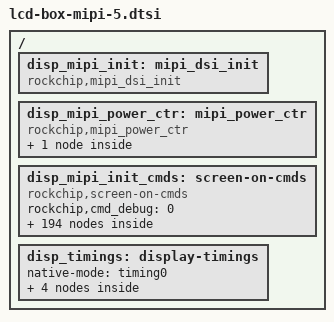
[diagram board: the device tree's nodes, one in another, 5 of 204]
/*
 * RockChip. LCD_BOX mipi 5.1 720*1280 4line
 *
 */
#include <dt-bindings/input/input.h>
/ {

        /* about mipi */
		disp_mipi_init: mipi_dsi_init{
					compatible = "rockchip,mipi_dsi_init";
					rockchip,screen_init	= <0>;
					rockchip,dsi_lane		= <4>;
					rockchip,dsi_hs_clk		= <450>;//
					rockchip,mipi_dsi_num	= <1>;
		};
		disp_mipi_power_ctr: mipi_power_ctr {
					compatible = "rockchip,mipi_power_ctr";
					mipi_lcd_rst:mipi_lcd_rst {
							compatible = "rockchip,lcd_rst";
							rockchip,gpios = <&gpio8 GPIO_A7 GPIO_ACTIVE_HIGH>;
							rockchip,delay = <100>;
					};
		};
		disp_mipi_init_cmds: screen-on-cmds {
			compatible = "rockchip,screen-on-cmds";
			rockchip,cmd_debug = <0>;

			rockchip,on-cmds1 {
			compatible = "rockchip,on-cmds";
			rockchip,cmd_type = <LPDT>;
			rockchip,dsi_id = <0>;        
			rockchip,cmd = <0x39 0xFF 0x98 0x81 0x03>;
			rockchip,cmd_delay = <0>;
		    };

		    rockchip,on-cmds2 {
			compatible = "rockchip,on-cmds";
			rockchip,cmd_type = <LPDT>;
			rockchip,dsi_id = <0>;        
			rockchip,cmd = <0x15 0x01 0x00>;
			rockchip,cmd_delay = <0>;
		    };

		    rockchip,on-cmds3 {
			compatible = "rockchip,on-cmds";
			rockchip,cmd_type = <LPDT>;
			rockchip,dsi_id = <0>;     
			rockchip,cmd = <0x15 0x02 0X00>;
			rockchip,cmd_delay = <0>;
		    };

		    rockchip,on-cmds4 {
			compatible = "rockchip,on-cmds";
			rockchip,cmd_type = <LPDT>;
			rockchip,dsi_id = <0>;        
			rockchip,cmd = <0x15 0x03 0X53>;
			rockchip,cmd_delay = <0>;
		    };

		    rockchip,on-cmds5 {
			compatible = "rockchip,on-cmds";
			rockchip,cmd_type = <LPDT>;
			rockchip,dsi_id = <0>;        
			rockchip,cmd = <0x15 0X04 0X00>;
			rockchip,cmd_delay = <0>;
		    };

		    rockchip,on-cmds6 {
			compatible = "rockchip,on-cmds";
			rockchip,cmd_type = <LPDT>;
			rockchip,dsi_id = <0>;        
			rockchip,cmd = <0x15 0x05 0X00>;
			rockchip,cmd_delay = <0>;
		    };

		    rockchip,on-cmds7 {
			compatible = "rockchip,on-cmds";
			rockchip,cmd_type = <LPDT>;
			rockchip,dsi_id = <0>;      
			rockchip,cmd = <0x15 0x06 0x08>;
			rockchip,cmd_delay = <0>;
		    };

		    rockchip,on-cmds8 {
			compatible = "rockchip,on-cmds";
			rockchip,cmd_type = <LPDT>;
			rockchip,dsi_id = <0>;        
			rockchip,cmd = <0x15 0x07 0x00>;
			rockchip,cmd_delay = <0>;
		    };

		    rockchip,on-cmds9 {
			compatible = "rockchip,on-cmds";
			rockchip,cmd_type = <LPDT>;
			rockchip,dsi_id = <0>;        
			rockchip,cmd = <0x15 0x08 0x00>;
			rockchip,cmd_delay = <0>;
		    };
//////////////////////////////////////////////////
		    rockchip,on-cmds10 {
			compatible = "rockchip,on-cmds";
			rockchip,cmd_type = <LPDT>;
			rockchip,dsi_id = <0>;       
			rockchip,cmd = <0x15 0x09 0x00>;
			rockchip,cmd_delay = <0>;
		    };


		    rockchip,on-cmds11 {
			compatible = "rockchip,on-cmds";
			rockchip,cmd_type = <LPDT>;
			rockchip,dsi_id = <0>; 
			rockchip,cmd = <0x15 0X0A 0X00>;
			rockchip,cmd_delay = <0>;
		    };

		    rockchip,on-cmds12 {
			compatible = "rockchip,on-cmds";
			rockchip,cmd_type = <LPDT>;
			rockchip,dsi_id = <0>;      
			rockchip,cmd = <0x15 0X0b 0X00>;
			rockchip,cmd_delay = <0>;
		    };

		    rockchip,on-cmds13 {
			compatible = "rockchip,on-cmds";
			rockchip,cmd_type = <LPDT>;
			rockchip,dsi_id = <0>;        
			rockchip,cmd = <0x15 0x0C 0x00>;
			rockchip,cmd_delay = <0>;
		    };

		    rockchip,on-cmds14 {
			compatible = "rockchip,on-cmds";
			rockchip,cmd_type = <LPDT>;
			rockchip,dsi_id = <0>;    
			rockchip,cmd = <0x15 0x0d 0x00>;
			rockchip,cmd_delay = <0>;
		    };

		    rockchip,on-cmds15 {
			compatible = "rockchip,on-cmds";
			rockchip,cmd_type = <LPDT>;
			rockchip,dsi_id = <0>;     	  
			rockchip,cmd = <0x15  0X0e 0X00>;
			rockchip,cmd_delay = <0>;
		    };

		    rockchip,on-cmds16 {
			compatible = "rockchip,on-cmds";
			rockchip,cmd_type = <LPDT>;
			rockchip,dsi_id = <0>;    
			rockchip,cmd = <0x15 0x0f 0x26>;
			rockchip,cmd_delay = <0>;
		    };

		    //~~~~

		    rockchip,on-cmds17 {
			compatible = "rockchip,on-cmds";
			rockchip,cmd_type = <LPDT>;
			rockchip,dsi_id = <0>;       
			rockchip,cmd = <0x15 0x10 0x26>;
			rockchip,cmd_delay = <0>;
		    };

		    rockchip,on-cmds18 {
			compatible = "rockchip,on-cmds";
			rockchip,cmd_type = <LPDT>;
			rockchip,dsi_id = <0>;       
			rockchip,cmd = <0x15 0x11 0x00>;
			rockchip,cmd_delay = <0>;
		    };
		    rockchip,on-cmds19 {
			compatible = "rockchip,on-cmds";
			rockchip,cmd_type = <LPDT>;
			rockchip,dsi_id = <0>;       
			rockchip,cmd = <0x15 0x12 0x00>;
			rockchip,cmd_delay = <0>;
		    };
		    rockchip,on-cmds20 {
			compatible = "rockchip,on-cmds";
			rockchip,cmd_type = <LPDT>;
			rockchip,dsi_id = <0>;       
			rockchip,cmd = <0x15 0x13 0x00>;
			rockchip,cmd_delay = <0>;
		    };
		    rockchip,on-cmds21 {
			compatible = "rockchip,on-cmds";
			rockchip,cmd_type = <LPDT>;
			rockchip,dsi_id = <0>;       
			rockchip,cmd = <0x15 0x14 0x00>;
			rockchip,cmd_delay = <0>;
		    };
		    rockchip,on-cmds22 {
			compatible = "rockchip,on-cmds";
			rockchip,cmd_type = <LPDT>;
			rockchip,dsi_id = <0>;       
			rockchip,cmd = <0x15 0x15 0x00>;
			rockchip,cmd_delay = <0>;
		    };
		    rockchip,on-cmds23 {
			compatible = "rockchip,on-cmds";
			rockchip,cmd_type = <LPDT>;
			rockchip,dsi_id = <0>;       
			rockchip,cmd = <0x15 0x16 0x00>;
			rockchip,cmd_delay = <0>;
		    };
		    rockchip,on-cmds24 {
			compatible = "rockchip,on-cmds";
			rockchip,cmd_type = <LPDT>;
			rockchip,dsi_id = <0>;       
			rockchip,cmd = <0x15 0x17 0x00>;
			rockchip,cmd_delay = <0>;
		    };

		    rockchip,on-cmds25 {
			compatible = "rockchip,on-cmds";
			rockchip,cmd_type = <LPDT>;
			rockchip,dsi_id = <0>;       
			rockchip,cmd = <0x15 0x18 0x00>;
			rockchip,cmd_delay = <0>;
		    };
		    rockchip,on-cmds26 {
			compatible = "rockchip,on-cmds";
			rockchip,cmd_type = <LPDT>;
			rockchip,dsi_id = <0>;       
			rockchip,cmd = <0x15 0x19 0x00>;
			rockchip,cmd_delay = <0>;
		    };
		    rockchip,on-cmds27 {
			compatible = "rockchip,on-cmds";
			rockchip,cmd_type = <LPDT>;
			rockchip,dsi_id = <0>;       
			rockchip,cmd = <0x15 0x1a 0x00>;
			rockchip,cmd_delay = <0>;
		    };
		    rockchip,on-cmds28 {
			compatible = "rockchip,on-cmds";
			rockchip,cmd_type = <LPDT>;
			rockchip,dsi_id = <0>;       
			rockchip,cmd = <0x15 0x1b 0x00>;
			rockchip,cmd_delay = <0>;
		    };

		    rockchip,on-cmds29 {
			compatible = "rockchip,on-cmds";
			rockchip,cmd_type = <LPDT>;
			rockchip,dsi_id = <0>;       
			rockchip,cmd = <0x15 0x1c 0x00>;
			rockchip,cmd_delay = <0>;
		    };
		    rockchip,on-cmds30 {
			compatible = "rockchip,on-cmds";
			rockchip,cmd_type = <LPDT>;
			rockchip,dsi_id = <0>;       
			rockchip,cmd = <0x15 0x1d 0x00>;
			rockchip,cmd_delay = <0>;
		    };
		    rockchip,on-cmds31 {
			compatible = "rockchip,on-cmds";
			rockchip,cmd_type = <LPDT>;
			rockchip,dsi_id = <0>;       
			rockchip,cmd = <0x15 0x1e 0x40>;
			rockchip,cmd_delay = <0>;
		    };
		    rockchip,on-cmds32 {
			compatible = "rockchip,on-cmds";
			rockchip,cmd_type = <LPDT>;
			rockchip,dsi_id = <0>;       
			rockchip,cmd = <0x15 0x1f 0xc0>;
			rockchip,cmd_delay = <0>;
		    };

		    /////////////////////////////////////
		    

		    rockchip,on-cmds33 {
			compatible = "rockchip,on-cmds";
			rockchip,cmd_type = <LPDT>;
			rockchip,dsi_id = <0>;       
			rockchip,cmd = <0x15 0x20 0x06>;
			rockchip,cmd_delay = <0>;
		    };


		    rockchip,on-cmds34 {
			compatible = "rockchip,on-cmds";
			rockchip,cmd_type = <LPDT>;
			rockchip,dsi_id = <0>; 
			rockchip,cmd = <0x15 0X21 0X01>;
			rockchip,cmd_delay = <0>;
		    };

		    rockchip,on-cmds35 {
			compatible = "rockchip,on-cmds";
			rockchip,cmd_type = <LPDT>;
			rockchip,dsi_id = <0>;      
			rockchip,cmd = <0x15 0X22 0X07>;
			rockchip,cmd_delay = <0>;
		    };

		    rockchip,on-cmds36 {
			compatible = "rockchip,on-cmds";
			rockchip,cmd_type = <LPDT>;
			rockchip,dsi_id = <0>;        
			rockchip,cmd = <0x15 0x23 0x00>;
			rockchip,cmd_delay = <0>;
		    };

		    rockchip,on-cmds37 {
			compatible = "rockchip,on-cmds";
			rockchip,cmd_type = <LPDT>;
			rockchip,dsi_id = <0>;    
			rockchip,cmd = <0x15 0x24 0x8a>;
			rockchip,cmd_delay = <0>;
		    };

		    rockchip,on-cmds38 {
			compatible = "rockchip,on-cmds";
			rockchip,cmd_type = <LPDT>;
			rockchip,dsi_id = <0>;     	  
			rockchip,cmd = <0x15  0X25 0x8a>;
			rockchip,cmd_delay = <0>;
		    };

		    rockchip,on-cmds39 {
			compatible = "rockchip,on-cmds";
			rockchip,cmd_type = <LPDT>;
			rockchip,dsi_id = <0>;    
			rockchip,cmd = <0x15 0x26 0x00>;
			rockchip,cmd_delay = <0>;
		    };

		    //~~~~

		    rockchip,on-cmds40 {
			compatible = "rockchip,on-cmds";
			rockchip,cmd_type = <LPDT>;
			rockchip,dsi_id = <0>;       
			rockchip,cmd = <0x15 0x27 0x00>;
			rockchip,cmd_delay = <0>;
		    };

		    rockchip,on-cmds41 {
			compatible = "rockchip,on-cmds";
			rockchip,cmd_type = <LPDT>;
			rockchip,dsi_id = <0>;       
			rockchip,cmd = <0x15 0x28 0x33>;
			rockchip,cmd_delay = <0>;
		    };
		    rockchip,on-cmds42 {
			compatible = "rockchip,on-cmds";
			rockchip,cmd_type = <LPDT>;
			rockchip,dsi_id = <0>;       
			rockchip,cmd = <0x15 0x29 0x33>;
			rockchip,cmd_delay = <0>;
		    };
		    rockchip,on-cmds43 {
			compatible = "rockchip,on-cmds";
			rockchip,cmd_type = <LPDT>;
			rockchip,dsi_id = <0>;       
			rockchip,cmd = <0x15 0x2a 0x00>;
			rockchip,cmd_delay = <0>;
		    };
		    rockchip,on-cmds44 {
			compatible = "rockchip,on-cmds";
			rockchip,cmd_type = <LPDT>;
			rockchip,dsi_id = <0>;       
			rockchip,cmd = <0x15 0x2b 0x00>;
			rockchip,cmd_delay = <0>;
		    };
		    rockchip,on-cmds45 {
			compatible = "rockchip,on-cmds";
			rockchip,cmd_type = <LPDT>;
			rockchip,dsi_id = <0>;       
			rockchip,cmd = <0x15 0x2c 0x08>;
			rockchip,cmd_delay = <0>;
		    };
		    rockchip,on-cmds46 {
			compatible = "rockchip,on-cmds";
			rockchip,cmd_type = <LPDT>;
			rockchip,dsi_id = <0>;       
			rockchip,cmd = <0x15 0x2d 0x08>;
			rockchip,cmd_delay = <0>;
		    };
		    rockchip,on-cmds47 {
			compatible = "rockchip,on-cmds";
			rockchip,cmd_type = <LPDT>;
			rockchip,dsi_id = <0>;       
			rockchip,cmd = <0x15 0x2e 0x0b>;
			rockchip,cmd_delay = <0>;
		    };

		    rockchip,on-cmds48 {
			compatible = "rockchip,on-cmds";
			rockchip,cmd_type = <LPDT>;
			rockchip,dsi_id = <0>;       
			rockchip,cmd = <0x15 0x2f 0x0b>;
			rockchip,cmd_delay = <0>;
		    };

		    ////////////////////////////////////

		    rockchip,on-cmds49 {
			compatible = "rockchip,on-cmds";
			rockchip,cmd_type = <LPDT>;
			rockchip,dsi_id = <0>;       
			rockchip,cmd = <0x15 0x30 0x00>;
			rockchip,cmd_delay = <0>;
		    };
		    rockchip,on-cmds50 {
			compatible = "rockchip,on-cmds";
			rockchip,cmd_type = <LPDT>;
			rockchip,dsi_id = <0>;       
			rockchip,cmd = <0x15 0x31 0x00>;
			rockchip,cmd_delay = <0>;
		    };
		    rockchip,on-cmds51 {
			compatible = "rockchip,on-cmds";
			rockchip,cmd_type = <LPDT>;
			rockchip,dsi_id = <0>;       
			rockchip,cmd = <0x15 0x32 0x42>;
			rockchip,cmd_delay = <0>;
		    };

		    rockchip,on-cmds52 {
			compatible = "rockchip,on-cmds";
			rockchip,cmd_type = <LPDT>;
			rockchip,dsi_id = <0>;       
			rockchip,cmd = <0x15 0x33 0x00>;
			rockchip,cmd_delay = <0>;
		    };
		    rockchip,on-cmds53 {
			compatible = "rockchip,on-cmds";
			rockchip,cmd_type = <LPDT>;
			rockchip,dsi_id = <0>;       
			rockchip,cmd = <0x15 0x34 0x00>;
			rockchip,cmd_delay = <0>;
		    };
		    rockchip,on-cmds54 {
			compatible = "rockchip,on-cmds";
			rockchip,cmd_type = <LPDT>;
			rockchip,dsi_id = <0>;       
			rockchip,cmd = <0x15 0x35 0X0A>;
			rockchip,cmd_delay = <0>;
		    };
		    rockchip,on-cmds55 {
			compatible = "rockchip,on-cmds";
			rockchip,cmd_type = <LPDT>;
			rockchip,dsi_id = <0>;       
			rockchip,cmd = <0x15 0x36 0x00>;
			rockchip,cmd_delay = <0>;
		    };
 			 rockchip,on-cmds56 {
			compatible = "rockchip,on-cmds";
			rockchip,cmd_type = <LPDT>;
			rockchip,dsi_id = <0>;       
			rockchip,cmd = <0x15 0x37 0x08>;
			rockchip,cmd_delay = <0>;
		    };
		    rockchip,on-cmds57 {
			compatible = "rockchip,on-cmds";
			rockchip,cmd_type = <LPDT>;
			rockchip,dsi_id = <0>;       
			rockchip,cmd = <0x15 0x38 0x3c>;
			rockchip,cmd_delay = <0>;
		    };
		    rockchip,on-cmds58 {
			compatible = "rockchip,on-cmds";
			rockchip,cmd_type = <LPDT>;
			rockchip,dsi_id = <0>;       
			rockchip,cmd = <0x15 0x39 0x00>;
			rockchip,cmd_delay = <0>;
		    };

		    rockchip,on-cmds59 {
			compatible = "rockchip,on-cmds";
			rockchip,cmd_type = <LPDT>;
			rockchip,dsi_id = <0>;       
			rockchip,cmd = <0x15 0x3a 0x00>;
			rockchip,cmd_delay = <0>;
		    };
		    rockchip,on-cmds60 {
			compatible = "rockchip,on-cmds";
			rockchip,cmd_type = <LPDT>;
			rockchip,dsi_id = <0>;       
			rockchip,cmd = <0x15 0x3b 0x00>;
			rockchip,cmd_delay = <0>;
		    };
		    rockchip,on-cmds61 {
			compatible = "rockchip,on-cmds";
			rockchip,cmd_type = <LPDT>;
			rockchip,dsi_id = <0>;       
			rockchip,cmd = <0x15 0x3c 0X00>;
			rockchip,cmd_delay = <0>;
		    };
		    rockchip,on-cmds62 {
			compatible = "rockchip,on-cmds";
			rockchip,cmd_type = <LPDT>;
			rockchip,dsi_id = <0>;       
			rockchip,cmd = <0x15 0x3d 0x00>;
			rockchip,cmd_delay = <0>;
		    };
		    rockchip,on-cmds63 {
			compatible = "rockchip,on-cmds";
			rockchip,cmd_type = <LPDT>;
			rockchip,dsi_id = <0>;       
			rockchip,cmd = <0x15 0x3e 0X00>;
			rockchip,cmd_delay = <0>;
		    };
		    rockchip,on-cmds64 {
			compatible = "rockchip,on-cmds";
			rockchip,cmd_type = <LPDT>;
			rockchip,dsi_id = <0>;       
			rockchip,cmd = <0x15 0x3f 0x00>;
			rockchip,cmd_delay = <0>;
		    };
		    /////////////////////////////////////
		    rockchip,on-cmds65 {
			compatible = "rockchip,on-cmds";
			rockchip,cmd_type = <LPDT>;
			rockchip,dsi_id = <0>;       
			rockchip,cmd = <0x15 0x40 0x00>;
			rockchip,cmd_delay = <0>;
		    };
		    rockchip,on-cmds66 {
			compatible = "rockchip,on-cmds";
			rockchip,cmd_type = <LPDT>;
			rockchip,dsi_id = <0>;       
			rockchip,cmd = <0x15 0x41 0x00>;
			rockchip,cmd_delay = <0>;
		    };
		    rockchip,on-cmds67 {
			compatible = "rockchip,on-cmds";
			rockchip,cmd_type = <LPDT>;
			rockchip,dsi_id = <0>;       
			rockchip,cmd = <0x15 0x42 0x42>;
			rockchip,cmd_delay = <0>;
		    };

		    rockchip,on-cmds68 {
			compatible = "rockchip,on-cmds";
			rockchip,cmd_type = <LPDT>;
			rockchip,dsi_id = <0>;       
			rockchip,cmd = <0x15 0x43 0x08>;
			rockchip,cmd_delay = <0>;
		    };
		    rockchip,on-cmds69 {
			compatible = "rockchip,on-cmds";
			rockchip,cmd_type = <LPDT>;
			rockchip,dsi_id = <0>;       
			rockchip,cmd = <0x15 0x44 0x00>;
			rockchip,cmd_delay = <0>;
		    };

		    ///////////////////////////////
		    rockchip,on-cmds70 {
			compatible = "rockchip,on-cmds";
			rockchip,cmd_type = <LPDT>;
			rockchip,dsi_id = <0>;       
			rockchip,cmd = <0x15 0x50 0X01>;
			rockchip,cmd_delay = <0>;
		    };
		    rockchip,on-cmds71 {
			compatible = "rockchip,on-cmds";
			rockchip,cmd_type = <LPDT>;
			rockchip,dsi_id = <0>;       
			rockchip,cmd = <0x15 0x51 0x23>;
			rockchip,cmd_delay = <0>;
		    };
 			 rockchip,on-cmds72 {
			compatible = "rockchip,on-cmds";
			rockchip,cmd_type = <LPDT>;
			rockchip,dsi_id = <0>;       
			rockchip,cmd = <0x15 0x52 0x45>;
			rockchip,cmd_delay = <0>;
		    };
		    rockchip,on-cmds73 {
			compatible = "rockchip,on-cmds";
			rockchip,cmd_type = <LPDT>;
			rockchip,dsi_id = <0>;       
			rockchip,cmd = <0x15 0x53 0x67>;
			rockchip,cmd_delay = <0>;
		    };
		    rockchip,on-cmds74 {
			compatible = "rockchip,on-cmds";
			rockchip,cmd_type = <LPDT>;
			rockchip,dsi_id = <0>;       
			rockchip,cmd = <0x15 0x54 0x89>;
			rockchip,cmd_delay = <0>;
		    };

		    rockchip,on-cmds75 {
			compatible = "rockchip,on-cmds";
			rockchip,cmd_type = <LPDT>;
			rockchip,dsi_id = <0>;       
			rockchip,cmd = <0x15 0x55 0xab>;
			rockchip,cmd_delay = <0>;
		    };
		    rockchip,on-cmds76 {
			compatible = "rockchip,on-cmds";
			rockchip,cmd_type = <LPDT>;
			rockchip,dsi_id = <0>;       
			rockchip,cmd = <0x15 0x56 0x01>;
			rockchip,cmd_delay = <0>;
		    };
		    rockchip,on-cmds77 {
			compatible = "rockchip,on-cmds";
			rockchip,cmd_type = <LPDT>;
			rockchip,dsi_id = <0>;       
			rockchip,cmd = <0x15 0x57 0X23>;
			rockchip,cmd_delay = <0>;
		    };
		    rockchip,on-cmds78 {
			compatible = "rockchip,on-cmds";
			rockchip,cmd_type = <LPDT>;
			rockchip,dsi_id = <0>;       
			rockchip,cmd = <0x15 0x58 0x45>;
			rockchip,cmd_delay = <0>;
		    };
		    rockchip,on-cmds79 {
			compatible = "rockchip,on-cmds";
			rockchip,cmd_type = <LPDT>;
			rockchip,dsi_id = <0>;       
			rockchip,cmd = <0x15 0x59 0X67>;
			rockchip,cmd_delay = <0>;
		    };
		    rockchip,on-cmds80 {
			compatible = "rockchip,on-cmds";
			rockchip,cmd_type = <LPDT>;
			rockchip,dsi_id = <0>;       
			rockchip,cmd = <0x15 0x5a 0x89>;
			rockchip,cmd_delay = <0>;
		    };
		    rockchip,on-cmds81 {
			compatible = "rockchip,on-cmds";
			rockchip,cmd_type = <LPDT>;
			rockchip,dsi_id = <0>;       
			rockchip,cmd = <0x15 0x5b 0xab>;
			rockchip,cmd_delay = <0>;
		    };
		    rockchip,on-cmds82 {
			compatible = "rockchip,on-cmds";
			rockchip,cmd_type = <LPDT>;
			rockchip,dsi_id = <0>;       
			rockchip,cmd = <0x15 0x5c 0xcd>;
			rockchip,cmd_delay = <0>;
		    };

		    rockchip,on-cmds83 {
			compatible = "rockchip,on-cmds";
			rockchip,cmd_type = <LPDT>;
			rockchip,dsi_id = <0>;       
			rockchip,cmd = <0x15 0x5d 0xef>;
			rockchip,cmd_delay = <0>;
		    };
		    rockchip,on-cmds84 {
			compatible = "rockchip,on-cmds";
			rockchip,cmd_type = <LPDT>;
			rockchip,dsi_id = <0>;       
			rockchip,cmd = <0x15 0x5e 0x00>;
			rockchip,cmd_delay = <0>;
		    };
		    rockchip,on-cmds85 {
			compatible = "rockchip,on-cmds";
			rockchip,cmd_type = <LPDT>;
			rockchip,dsi_id = <0>;       
			rockchip,cmd = <0x15 0x5f 0X01>;
			rockchip,cmd_delay = <0>;
		    };

		    ///////////////////////

		      rockchip,on-cmds86 {
			compatible = "rockchip,on-cmds";
			rockchip,cmd_type = <LPDT>;
			rockchip,dsi_id = <0>;       
			rockchip,cmd = <0x15 0x60 0X01>;
			rockchip,cmd_delay = <0>;
		    };
		    rockchip,on-cmds87 {
			compatible = "rockchip,on-cmds";
			rockchip,cmd_type = <LPDT>;
			rockchip,dsi_id = <0>;       
			rockchip,cmd = <0x15 0x61 0x06>;
			rockchip,cmd_delay = <0>;
		    };
 			 rockchip,on-cmds88 {
			compatible = "rockchip,on-cmds";
			rockchip,cmd_type = <LPDT>;
			rockchip,dsi_id = <0>;       
			rockchip,cmd = <0x15 0x62 0x06>;
			rockchip,cmd_delay = <0>;
		    };
		    rockchip,on-cmds89 {
			compatible = "rockchip,on-cmds";
			rockchip,cmd_type = <LPDT>;
			rockchip,dsi_id = <0>;       
			rockchip,cmd = <0x15 0x63 0x06>;
			rockchip,cmd_delay = <0>;
		    };
		    rockchip,on-cmds90 {
			compatible = "rockchip,on-cmds";
			rockchip,cmd_type = <LPDT>;
			rockchip,dsi_id = <0>;       
			rockchip,cmd = <0x15 0x64 0x06>;
			rockchip,cmd_delay = <0>;
		    };

		    rockchip,on-cmds91 {
			compatible = "rockchip,on-cmds";
			rockchip,cmd_type = <LPDT>;
			rockchip,dsi_id = <0>;       
			rockchip,cmd = <0x15 0x65 0x00>;
			rockchip,cmd_delay = <0>;
		    };
		    rockchip,on-cmds92 {
			compatible = "rockchip,on-cmds";
			rockchip,cmd_type = <LPDT>;
			rockchip,dsi_id = <0>;       
			rockchip,cmd = <0x15 0x66 0x00>;
			rockchip,cmd_delay = <0>;
		    };
		    rockchip,on-cmds93 {
			compatible = "rockchip,on-cmds";
			rockchip,cmd_type = <LPDT>;
			rockchip,dsi_id = <0>;       
			rockchip,cmd = <0x15 0x67 0X17>;
			rockchip,cmd_delay = <0>;
		    };
		    rockchip,on-cmds94 {
			compatible = "rockchip,on-cmds";
			rockchip,cmd_type = <LPDT>;
			rockchip,dsi_id = <0>;       
			rockchip,cmd = <0x15 0x68 0x02>;
			rockchip,cmd_delay = <0>;
		    };
		    rockchip,on-cmds95 {
			compatible = "rockchip,on-cmds";
			rockchip,cmd_type = <LPDT>;
			rockchip,dsi_id = <0>;       
			rockchip,cmd = <0x15 0x69 0X02>;
			rockchip,cmd_delay = <0>;
		    };
		    rockchip,on-cmds96 {
			compatible = "rockchip,on-cmds";
			rockchip,cmd_type = <LPDT>;
			rockchip,dsi_id = <0>;       
			rockchip,cmd = <0x15 0x6a 0x16>;
			rockchip,cmd_delay = <0>;
		    };
		    rockchip,on-cmds97 {
			compatible = "rockchip,on-cmds";
			rockchip,cmd_type = <LPDT>;
			rockchip,dsi_id = <0>;       
			rockchip,cmd = <0x15 0x6b 0x02>;
			rockchip,cmd_delay = <0>;
		    };
		    rockchip,on-cmds98 {
			compatible = "rockchip,on-cmds";
			rockchip,cmd_type = <LPDT>;
			rockchip,dsi_id = <0>;       
			rockchip,cmd = <0x15 0x6c 0x0d>;
			rockchip,cmd_delay = <0>;
		    };

		    rockchip,on-cmds99 {
			compatible = "rockchip,on-cmds";
			rockchip,cmd_type = <LPDT>;
			rockchip,dsi_id = <0>;       
			rockchip,cmd = <0x15 0x6d 0x0d>;
			rockchip,cmd_delay = <0>;
		    };
		    rockchip,on-cmds100 {
			compatible = "rockchip,on-cmds";
			rockchip,cmd_type = <LPDT>;
			rockchip,dsi_id = <0>;       
			rockchip,cmd = <0x15 0x6e 0x0C>;
			rockchip,cmd_delay = <0>;
		    };
		    rockchip,on-cmds101 {
			compatible = "rockchip,on-cmds";
			rockchip,cmd_type = <LPDT>;
			rockchip,dsi_id = <0>;       
			rockchip,cmd = <0x15 0x6f 0x0C>;
			rockchip,cmd_delay = <0>;
		    };
/////////////////////////////


		      rockchip,on-cmds102 {
			compatible = "rockchip,on-cmds";
			rockchip,cmd_type = <LPDT>;
			rockchip,dsi_id = <0>;       
			rockchip,cmd = <0x15 0x70 0x0f>;
			rockchip,cmd_delay = <0>;
		    };
		    rockchip,on-cmds103 {
			compatible = "rockchip,on-cmds";
			rockchip,cmd_type = <LPDT>;
			rockchip,dsi_id = <0>;       
			rockchip,cmd = <0x15 0x71 0x0f>;
			rockchip,cmd_delay = <0>;
		    };
 			 rockchip,on-cmds104 {
			compatible = "rockchip,on-cmds";
			rockchip,cmd_type = <LPDT>;
			rockchip,dsi_id = <0>;       
			rockchip,cmd = <0x15 0x72 0x0e>;
			rockchip,cmd_delay = <0>;
		    };
		    rockchip,on-cmds105 {
			compatible = "rockchip,on-cmds";
			rockchip,cmd_type = <LPDT>;
			rockchip,dsi_id = <0>;       
			rockchip,cmd = <0x15 0x73 0X0e>;
			rockchip,cmd_delay = <0>;
		    };
		    rockchip,on-cmds106 {
			compatible = "rockchip,on-cmds";
			rockchip,cmd_type = <LPDT>;
			rockchip,dsi_id = <0>;       
			rockchip,cmd = <0x15 0x74 0x02>;
			rockchip,cmd_delay = <0>;
		    };

		    rockchip,on-cmds107 {
			compatible = "rockchip,on-cmds";
			rockchip,cmd_type = <LPDT>;
			rockchip,dsi_id = <0>;       
			rockchip,cmd = <0x15 0x75 0x01>;
			rockchip,cmd_delay = <0>;
		    };
		    rockchip,on-cmds108 {
			compatible = "rockchip,on-cmds";
			rockchip,cmd_type = <LPDT>;
			rockchip,dsi_id = <0>;       
			rockchip,cmd = <0x15 0x76 0x01>;
			rockchip,cmd_delay = <0>;
		    };
		    rockchip,on-cmds109 {
			compatible = "rockchip,on-cmds";
			rockchip,cmd_type = <LPDT>;
			rockchip,dsi_id = <0>;       
			rockchip,cmd = <0x15 0x77 0X06>;
			rockchip,cmd_delay = <0>;
		    };
		    rockchip,on-cmds110 {
			compatible = "rockchip,on-cmds";
			rockchip,cmd_type = <LPDT>;
			rockchip,dsi_id = <0>;       
			rockchip,cmd = <0x15 0x78 0x06>;
			rockchip,cmd_delay = <0>;
		    };
		    rockchip,on-cmds111 {
			compatible = "rockchip,on-cmds";
			rockchip,cmd_type = <LPDT>;
			rockchip,dsi_id = <0>;       
			rockchip,cmd = <0x15 0x79 0X06>;
			rockchip,cmd_delay = <0>;
		    };
		    rockchip,on-cmds112 {
			compatible = "rockchip,on-cmds";
			rockchip,cmd_type = <LPDT>;
			rockchip,dsi_id = <0>;       
			rockchip,cmd = <0x15 0x7a 0x06>;
			rockchip,cmd_delay = <0>;
		    };
		    rockchip,on-cmds113 {
			compatible = "rockchip,on-cmds";
			rockchip,cmd_type = <LPDT>;
			rockchip,dsi_id = <0>;       
			rockchip,cmd = <0x15 0x7b 0x00>;
			rockchip,cmd_delay = <0>;
		    };
		    rockchip,on-cmds114 {
			compatible = "rockchip,on-cmds";
			rockchip,cmd_type = <LPDT>;
			rockchip,dsi_id = <0>;       
			rockchip,cmd = <0x15 0x7c 0x00>;
			rockchip,cmd_delay = <0>;
		    };

		    rockchip,on-cmds115 {
			compatible = "rockchip,on-cmds";
			rockchip,cmd_type = <LPDT>;
			rockchip,dsi_id = <0>;       
			rockchip,cmd = <0x15 0x7d 0x17>;
			rockchip,cmd_delay = <0>;
		    };
		    rockchip,on-cmds116 {
			compatible = "rockchip,on-cmds";
			rockchip,cmd_type = <LPDT>;
			rockchip,dsi_id = <0>;       
			rockchip,cmd = <0x15 0x7e 0x02>;
			rockchip,cmd_delay = <0>;
		    };
		    rockchip,on-cmds117 {
			compatible = "rockchip,on-cmds";
			rockchip,cmd_type = <LPDT>;
			rockchip,dsi_id = <0>;       
			rockchip,cmd = <0x15 0x7f 0x16>;
			rockchip,cmd_delay = <0>;
		    };
//////////////////////////

		      rockchip,on-cmds118 {
			compatible = "rockchip,on-cmds";
			rockchip,cmd_type = <LPDT>;
			rockchip,dsi_id = <0>;       
			rockchip,cmd = <0x15 0x80 0x16>;
			rockchip,cmd_delay = <0>;
		    };
		    rockchip,on-cmds119 {
			compatible = "rockchip,on-cmds";
			rockchip,cmd_type = <LPDT>;
			rockchip,dsi_id = <0>;       
			rockchip,cmd = <0x15 0x81 0x02>;
			rockchip,cmd_delay = <0>;
		    };
 			 rockchip,on-cmds120 {
			compatible = "rockchip,on-cmds";
			rockchip,cmd_type = <LPDT>;
			rockchip,dsi_id = <0>;       
			rockchip,cmd = <0x15 0x82 0x0D>;
			rockchip,cmd_delay = <0>;
		    };
		    rockchip,on-cmds121 {
			compatible = "rockchip,on-cmds";
			rockchip,cmd_type = <LPDT>;
			rockchip,dsi_id = <0>;       
			rockchip,cmd = <0x15 0x83 0x0D>;
			rockchip,cmd_delay = <0>;
		    };
		    rockchip,on-cmds122 {
			compatible = "rockchip,on-cmds";
			rockchip,cmd_type = <LPDT>;
			rockchip,dsi_id = <0>;       
			rockchip,cmd = <0x15 0x84 0x0C>;
			rockchip,cmd_delay = <0>;
		    };

		    rockchip,on-cmds123 {
			compatible = "rockchip,on-cmds";
			rockchip,cmd_type = <LPDT>;
			rockchip,dsi_id = <0>;       
			rockchip,cmd = <0x15 0x85 0x0C>;
			rockchip,cmd_delay = <0>;
		    };
		    rockchip,on-cmds124 {
			compatible = "rockchip,on-cmds";
			rockchip,cmd_type = <LPDT>;
			rockchip,dsi_id = <0>;       
			rockchip,cmd = <0x15 0x86 0x0f>;
			rockchip,cmd_delay = <0>;
		    };
		    rockchip,on-cmds125 {
			compatible = "rockchip,on-cmds";
			rockchip,cmd_type = <LPDT>;
			rockchip,dsi_id = <0>;       
			rockchip,cmd = <0x15 0x87 0x0f>;
			rockchip,cmd_delay = <0>;
		    };
		    rockchip,on-cmds126 {
			compatible = "rockchip,on-cmds";
			rockchip,cmd_type = <LPDT>;
			rockchip,dsi_id = <0>;       
			rockchip,cmd = <0x15 0x88 0X0e>;
			rockchip,cmd_delay = <0>;
		    };
		    rockchip,on-cmds127 {
			compatible = "rockchip,on-cmds";
			rockchip,cmd_type = <LPDT>;
			rockchip,dsi_id = <0>;       
			rockchip,cmd = <0x15 0x89 0X0e>;
			rockchip,cmd_delay = <0>;
		    };
		    rockchip,on-cmds128 {
			compatible = "rockchip,on-cmds";
			rockchip,cmd_type = <LPDT>;
			rockchip,dsi_id = <0>;       
			rockchip,cmd = <0x15 0x8a 0x02>;
			rockchip,cmd_delay = <0>;
		    };

		    //////////////////////
		    rockchip,on-cmds129 {
			compatible = "rockchip,on-cmds";
			rockchip,cmd_type = <LPDT>;
			rockchip,dsi_id = <0>;       
			rockchip,cmd = <0x39 0xff 0x98 0x81 0x04>;
			rockchip,cmd_delay = <0>;
		    };


		    ///////////////

		    rockchip,on-cmds130 {
			compatible = "rockchip,on-cmds";
			rockchip,cmd_type = <LPDT>;
			rockchip,dsi_id = <0>;       
			rockchip,cmd = <0x15 0x6e 0x2b>;
			rockchip,cmd_delay = <0>;
		    };

		    rockchip,on-cmds131 {
			compatible = "rockchip,on-cmds";
			rockchip,cmd_type = <LPDT>;
			rockchip,dsi_id = <0>;       
			rockchip,cmd = <0x15 0x6f 0x35>;
			rockchip,cmd_delay = <0>;
		    };

		    rockchip,on-cmds132 {
			compatible = "rockchip,on-cmds";
			rockchip,cmd_type = <LPDT>;
			rockchip,dsi_id = <0>;       
			rockchip,cmd = <0x15 0x3a 0xa4>;
			rockchip,cmd_delay = <0>;
		    };

		    rockchip,on-cmds133 {
			compatible = "rockchip,on-cmds";
			rockchip,cmd_type = <LPDT>;
			rockchip,dsi_id = <0>;       
			rockchip,cmd = <0x15 0x8d 0x1a>;
			rockchip,cmd_delay = <0>;
		    };

		    rockchip,on-cmds134 {
			compatible = "rockchip,on-cmds";
			rockchip,cmd_type = <LPDT>;
			rockchip,dsi_id = <0>;       
			rockchip,cmd = <0x15 0x87 0xba>;
			rockchip,cmd_delay = <0>;
		    };
		    rockchip,on-cmds135 {
			compatible = "rockchip,on-cmds";
			rockchip,cmd_type = <LPDT>;
			rockchip,dsi_id = <0>;       
			rockchip,cmd = <0x15 0xb2 0xd1>;
			rockchip,cmd_delay = <0>;
		    };

		    rockchip,on-cmds136 {
			compatible = "rockchip,on-cmds";
			rockchip,cmd_type = <LPDT>;
			rockchip,dsi_id = <0>;       
			rockchip,cmd = <0x15 0x88 0X0b>;
			rockchip,cmd_delay = <0>;
		    };
		    rockchip,on-cmds137 {
			compatible = "rockchip,on-cmds";
			rockchip,cmd_type = <LPDT>;
			rockchip,dsi_id = <0>;       
			rockchip,cmd = <0x15 0x38 0x01>;
			rockchip,cmd_delay = <0>;
		    };
		    rockchip,on-cmds138 {
			compatible = "rockchip,on-cmds";
			rockchip,cmd_type = <LPDT>;
			rockchip,dsi_id = <0>;       
			rockchip,cmd = <0x15 0x39 0x00>;
			rockchip,cmd_delay = <0>;
		    };
		    rockchip,on-cmds139 {
			compatible = "rockchip,on-cmds";
			rockchip,cmd_type = <LPDT>;
			rockchip,dsi_id = <0>;       
			rockchip,cmd = <0x15 0xb5 0x07>;
			rockchip,cmd_delay = <0>;
		    };
		    rockchip,on-cmds140 {
			compatible = "rockchip,on-cmds";
			rockchip,cmd_type = <LPDT>;
			rockchip,dsi_id = <0>;       
			rockchip,cmd = <0x15 0x31 0x75>;
			rockchip,cmd_delay = <0>;
		    };
		    rockchip,on-cmds141 {
			compatible = "rockchip,on-cmds";
			rockchip,cmd_type = <LPDT>;
			rockchip,dsi_id = <0>;       
			rockchip,cmd = <0x15 0x3b 0x98>;
			rockchip,cmd_delay = <0>;
		    };


//////////////////////////////////


		    rockchip,on-cmds142 {
			compatible = "rockchip,on-cmds";
			rockchip,cmd_type = <LPDT>;
			rockchip,dsi_id = <0>;       
			rockchip,cmd = <0x39 0xFF 0x98 0x81 0x01>;
			rockchip,cmd_delay = <0>;
		    };
		    rockchip,on-cmds143 {
			compatible = "rockchip,on-cmds";
			rockchip,cmd_type = <LPDT>;
			rockchip,dsi_id = <0>;       
			rockchip,cmd = <0x15 0x22 0x0a>;
			rockchip,cmd_delay = <0>;
		    };

		    rockchip,on-cmds144 {
			compatible = "rockchip,on-cmds";
			rockchip,cmd_type = <LPDT>;
			rockchip,dsi_id = <0>;       
			rockchip,cmd = <0x15 0x31 0x00>;
			rockchip,cmd_delay = <0>;
		    };
		    rockchip,on-cmds145 {
			compatible = "rockchip,on-cmds";
			rockchip,cmd_type = <LPDT>;
			rockchip,dsi_id = <0>;       
			rockchip,cmd = <0x15 0x53 0x40>;
			rockchip,cmd_delay = <0>;
		    };
		    rockchip,on-cmds146 {
			compatible = "rockchip,on-cmds";
			rockchip,cmd_type = <LPDT>;
			rockchip,dsi_id = <0>;       
			rockchip,cmd = <0x15 0x55 0x40>;
			rockchip,cmd_delay = <0>;
		    };

		    		    rockchip,on-cmds147 {
			compatible = "rockchip,on-cmds";
			rockchip,cmd_type = <LPDT>;
			rockchip,dsi_id = <0>;       
			rockchip,cmd = <0x50 0x95>;
			rockchip,cmd_delay = <0>;
		    };
		    rockchip,on-cmds148 {
			compatible = "rockchip,on-cmds";
			rockchip,cmd_type = <LPDT>;
			rockchip,dsi_id = <0>;       
			rockchip,cmd = <0x15 0x51 0x90>;
			rockchip,cmd_delay = <0>;
		    };

		    rockchip,on-cmds149 {
			compatible = "rockchip,on-cmds";
			rockchip,cmd_type = <LPDT>;
			rockchip,dsi_id = <0>;       
			rockchip,cmd = <0x15 0x60 0x22>;
			rockchip,cmd_delay = <0>;
		    };
		    rockchip,on-cmds150 {
			compatible = "rockchip,on-cmds";
			rockchip,cmd_type = <LPDT>;
			rockchip,dsi_id = <0>;       
			rockchip,cmd = <0x15 0x62 0x20>;
			rockchip,cmd_delay = <0>;
		    };
///////////////////////////

		    rockchip,on-cmds151 {
			compatible = "rockchip,on-cmds";
			rockchip,cmd_type = <LPDT>;
			rockchip,dsi_id = <0>;       
			rockchip,cmd = <0x15 0xA0 0x00>;
			rockchip,cmd_delay = <0>;
		    };

		    rockchip,on-cmds152 {
			compatible = "rockchip,on-cmds";
			rockchip,cmd_type = <LPDT>;
			rockchip,dsi_id = <0>;       
			rockchip,cmd = <0x15 0xa1 0x1b>;
			rockchip,cmd_delay = <0>;
		    };
		    rockchip,on-cmds153 {
			compatible = "rockchip,on-cmds";
			rockchip,cmd_type = <LPDT>;
			rockchip,dsi_id = <0>;       
			rockchip,cmd = <0x15 0xa2 0x2a>;
			rockchip,cmd_delay = <0>;
		    };
		    rockchip,on-cmds154 {
			compatible = "rockchip,on-cmds";
			rockchip,cmd_type = <LPDT>;
			rockchip,dsi_id = <0>;       
			rockchip,cmd = <0x15 0xa3 0x14>;
			rockchip,cmd_delay = <0>;
		    };

		    rockchip,on-cmds155 {
			compatible = "rockchip,on-cmds";
			rockchip,cmd_type = <LPDT>;
			rockchip,dsi_id = <0>;       
			rockchip,cmd = <0x15 0xa4 0x17>;
			rockchip,cmd_delay = <0>;
		    };
		    rockchip,on-cmds156 {
			compatible = "rockchip,on-cmds";
			rockchip,cmd_type = <LPDT>;
			rockchip,dsi_id = <0>;       
			rockchip,cmd = <0x15 0xa5 0x2b>;
			rockchip,cmd_delay = <0>;
		    };

		    rockchip,on-cmds157 {
			compatible = "rockchip,on-cmds";
			rockchip,cmd_type = <LPDT>;
			rockchip,dsi_id = <0>;       
			rockchip,cmd = <0x15 0xa6 0x1f>;
			rockchip,cmd_delay = <0>;
		    };
		    rockchip,on-cmds158 {
			compatible = "rockchip,on-cmds";
			rockchip,cmd_type = <LPDT>;
			rockchip,dsi_id = <0>;       
			rockchip,cmd = <0x15 0xa7 0x20>;
			rockchip,cmd_delay = <0>;
		    };


		    rockchip,on-cmds159 {
			compatible = "rockchip,on-cmds";
			rockchip,cmd_type = <LPDT>;
			rockchip,dsi_id = <0>;       
			rockchip,cmd = <0x15 0xA8 0x93>;
			rockchip,cmd_delay = <0>;
		    };

		    rockchip,on-cmds160 {
			compatible = "rockchip,on-cmds";
			rockchip,cmd_type = <LPDT>;
			rockchip,dsi_id = <0>;       
			rockchip,cmd = <0x15 0xa9 0x1e>;
			rockchip,cmd_delay = <0>;
		    };

		    rockchip,on-cmds161 {
			compatible = "rockchip,on-cmds";
			rockchip,cmd_type = <LPDT>;
			rockchip,dsi_id = <0>;       
			rockchip,cmd = <0x15 0xaa 0x2a>;
			rockchip,cmd_delay = <0>;
		    };

		    rockchip,on-cmds162 {
			compatible = "rockchip,on-cmds";
			rockchip,cmd_type = <LPDT>;
			rockchip,dsi_id = <0>;       
			rockchip,cmd = <0x15 0xab 0x7e>;
			rockchip,cmd_delay = <0>;
		    };
		    rockchip,on-cmds163 {
			compatible = "rockchip,on-cmds";
			rockchip,cmd_type = <LPDT>;
			rockchip,dsi_id = <0>;       
			rockchip,cmd = <0x15 0xac 0x1b>;
			rockchip,cmd_delay = <0>;
		    };

		    rockchip,on-cmds164 {
			compatible = "rockchip,on-cmds";
			rockchip,cmd_type = <LPDT>;
			rockchip,dsi_id = <0>;       
			rockchip,cmd = <0x15 0xad 0x19>;
			rockchip,cmd_delay = <0>;
		    };
		    rockchip,on-cmds165 {
			compatible = "rockchip,on-cmds";
			rockchip,cmd_type = <LPDT>;
			rockchip,dsi_id = <0>;       
			rockchip,cmd = <0x15 0xae 0x4c>;
			rockchip,cmd_delay = <0>;
		    };

		    rockchip,on-cmds166 {
			compatible = "rockchip,on-cmds";
			rockchip,cmd_type = <LPDT>;
			rockchip,dsi_id = <0>;       
			rockchip,cmd = <0x15 0xAf 0x22>;
			rockchip,cmd_delay = <0>;
		    };
/////////////////////////////////////////

		    rockchip,on-cmds167 {
			compatible = "rockchip,on-cmds";
			rockchip,cmd_type = <LPDT>;
			rockchip,dsi_id = <0>;       
			rockchip,cmd = <0x15 0xb0 0x28>;
			rockchip,cmd_delay = <0>;
		    };
		    rockchip,on-cmds168 {
			compatible = "rockchip,on-cmds";
			rockchip,cmd_type = <LPDT>;
			rockchip,dsi_id = <0>;       
			rockchip,cmd = <0x15 0xb1 0x4b>;
			rockchip,cmd_delay = <0>;
		    };
		    rockchip,on-cmds169 {
			compatible = "rockchip,on-cmds";
			rockchip,cmd_type = <LPDT>;
			rockchip,dsi_id = <0>;       
			rockchip,cmd = <0x15 0xb2 0x59>;
			rockchip,cmd_delay = <0>;
		    };

		    rockchip,on-cmds170 {
			compatible = "rockchip,on-cmds";
			rockchip,cmd_type = <LPDT>;
			rockchip,dsi_id = <0>;       
			rockchip,cmd = <0x15 0xb3 0x23>;
			rockchip,cmd_delay = <0>;
		    };
//////////////////////


		  
		    rockchip,on-cmds171 {
			compatible = "rockchip,on-cmds";
			rockchip,cmd_type = <LPDT>;
			rockchip,dsi_id = <0>;       
			rockchip,cmd = <0x15 0xc0 0x00>;
			rockchip,cmd_delay = <0>;
		    };

		    rockchip,on-cmds172 {
			compatible = "rockchip,on-cmds";
			rockchip,cmd_type = <LPDT>;
			rockchip,dsi_id = <0>;       
			rockchip,cmd = <0x15 0xc1 0x1b>;
			rockchip,cmd_delay = <0>;
		    };
		    rockchip,on-cmds173 {
			compatible = "rockchip,on-cmds";
			rockchip,cmd_type = <LPDT>;
			rockchip,dsi_id = <0>;       
			rockchip,cmd = <0x15 0xc2 0x2a>;
			rockchip,cmd_delay = <0>;
		    };
		    rockchip,on-cmds174 {
			compatible = "rockchip,on-cmds";
			rockchip,cmd_type = <LPDT>;
			rockchip,dsi_id = <0>;       
			rockchip,cmd = <0x15 0xc3 0x14>;
			rockchip,cmd_delay = <0>;
		    };

		    rockchip,on-cmds175 {
			compatible = "rockchip,on-cmds";
			rockchip,cmd_type = <LPDT>;
			rockchip,dsi_id = <0>;       
			rockchip,cmd = <0x15 0xc4 0x17>;
			rockchip,cmd_delay = <0>;
		    };
		    rockchip,on-cmds176 {
			compatible = "rockchip,on-cmds";
			rockchip,cmd_type = <LPDT>;
			rockchip,dsi_id = <0>;       
			rockchip,cmd = <0x15 0xc5 0x2b>;
			rockchip,cmd_delay = <0>;
		    };

		    rockchip,on-cmds177 {
			compatible = "rockchip,on-cmds";
			rockchip,cmd_type = <LPDT>;
			rockchip,dsi_id = <0>;       
			rockchip,cmd = <0x15 0xc6 0x1f>;
			rockchip,cmd_delay = <0>;
		    };
		    rockchip,on-cmds178 {
			compatible = "rockchip,on-cmds";
			rockchip,cmd_type = <LPDT>;
			rockchip,dsi_id = <0>;       
			rockchip,cmd = <0x15 0xc7 0x20>;
			rockchip,cmd_delay = <0>;
		    };


		    rockchip,on-cmds179 {
			compatible = "rockchip,on-cmds";
			rockchip,cmd_type = <LPDT>;
			rockchip,dsi_id = <0>;       
			rockchip,cmd = <0x15 0xc8 0x93>;
			rockchip,cmd_delay = <0>;
		    };

		    rockchip,on-cmds180 {
			compatible = "rockchip,on-cmds";
			rockchip,cmd_type = <LPDT>;
			rockchip,dsi_id = <0>;       
			rockchip,cmd = <0x15 0xc9 0x1e>;
			rockchip,cmd_delay = <0>;
		    };

		    rockchip,on-cmds181 {
			compatible = "rockchip,on-cmds";
			rockchip,cmd_type = <LPDT>;
			rockchip,dsi_id = <0>;       
			rockchip,cmd = <0x15 0xca 0x2a>;
			rockchip,cmd_delay = <0>;
		    };

		    rockchip,on-cmds182 {
			compatible = "rockchip,on-cmds";
			rockchip,cmd_type = <LPDT>;
			rockchip,dsi_id = <0>;       
			rockchip,cmd = <0x15 0xcb 0x7e>;
			rockchip,cmd_delay = <0>;
		    };
		    rockchip,on-cmds183 {
			compatible = "rockchip,on-cmds";
			rockchip,cmd_type = <LPDT>;
			rockchip,dsi_id = <0>;       
			rockchip,cmd = <0x15 0xcc 0x1b>;
			rockchip,cmd_delay = <0>;
		    };

		    rockchip,on-cmds184 {
			compatible = "rockchip,on-cmds";
			rockchip,cmd_type = <LPDT>;
			rockchip,dsi_id = <0>;       
			rockchip,cmd = <0x15 0xcd 0x19>;
			rockchip,cmd_delay = <0>;
		    };
		    rockchip,on-cmds185 {
			compatible = "rockchip,on-cmds";
			rockchip,cmd_type = <LPDT>;
			rockchip,dsi_id = <0>;       
			rockchip,cmd = <0x15 0xce 0x4c>;
			rockchip,cmd_delay = <0>;
		    };

		    rockchip,on-cmds186 {
			compatible = "rockchip,on-cmds";
			rockchip,cmd_type = <LPDT>;
			rockchip,dsi_id = <0>;       
			rockchip,cmd = <0x15 0xcf 0x22>;
			rockchip,cmd_delay = <0>;
		    };
///////////////////////////
		    rockchip,on-cmds187 {
			compatible = "rockchip,on-cmds";
			rockchip,cmd_type = <LPDT>;
			rockchip,dsi_id = <0>;       
			rockchip,cmd = <0x15 0xD0 0x28>;
			rockchip,cmd_delay = <0>;
		    };

		    rockchip,on-cmds188 {
			compatible = "rockchip,on-cmds";
			rockchip,cmd_type = <LPDT>;
			rockchip,dsi_id = <0>;       
			rockchip,cmd = <0x15 0xd1 0x4b>;
			rockchip,cmd_delay = <0>;
		    };
		    rockchip,on-cmds189 {
			compatible = "rockchip,on-cmds";
			rockchip,cmd_type = <LPDT>;
			rockchip,dsi_id = <0>;       
			rockchip,cmd = <0x15 0xd2 0x59>;
			rockchip,cmd_delay = <0>;
		    };

		    rockchip,on-cmds190 {
			compatible = "rockchip,on-cmds";
			rockchip,cmd_type = <LPDT>;
			rockchip,dsi_id = <0>;       
			rockchip,cmd = <0x15 0xd3 0x23>;
			rockchip,cmd_delay = <0>;
		    };

////
		    rockchip,on-cmds191 {
			compatible = "rockchip,on-cmds";
			rockchip,cmd_type = <LPDT>;
			rockchip,dsi_id = <0>;       
			rockchip,cmd = <0x39 0xff 0x98 0x81 0x00>;
			rockchip,cmd_delay = <0>;
		    };



///////////////////////////////////


//sleep out
		    rockchip,on-cmds192 {
			compatible = "rockchip,on-cmds";
			rockchip,cmd_type = <LPDT>;
			rockchip,dsi_id = <0>;        
			rockchip,cmd = <0x05 0x11>;
			rockchip,cmd_delay = <120>;//250
		    };

		    
///Display on
		    rockchip,on-cmds193 {
			compatible = "rockchip,on-cmds";
			rockchip,cmd_type = <LPDT>;
			rockchip,dsi_id = <0>;        
			rockchip,cmd = <0x05 0X29>;
			rockchip,cmd_delay = <50>;
		    };
		    
		    rockchip,on-cmds194 {
			compatible = "rockchip,on-cmds";
			rockchip,cmd_type = <LPDT>;
			rockchip,dsi_id = <0>;        
			rockchip,cmd = <0x15 0X35 0x00>;
			rockchip,cmd_delay = <0>;
		    };

		    };

		disp_timings: display-timings {
			native-mode = <&timing0>;
			timing0: timing0 {
				screen-type = <SCREEN_MIPI>;
				lvds-format = <LVDS_8BIT_2>;
				out-face    = <OUT_P888>;
				clock-frequency = <74488000>;
				hactive = <800>;
				vactive = <1280>;

				hback-porch = <30>;
				hfront-porch = <30>;
				vback-porch = <25>;
				vfront-porch = <25>;
				hsync-len = <5>;
				vsync-len = <10>;
				hsync-active = <0>;
				vsync-active = <0>;
				de-active = <0>;
				pixelclk-active = <0>;
				swap-rb = <0>;
				swap-rg = <0>;
				swap-gb = <0>;
                     	};
                     	timing1: timing1 {
				screen-type = <SCREEN_RGB>;
				out-face    = <OUT_P888>;
				color-mode = <COLOR_YCBCR>;
				clock-frequency = <38000000>;
				hactive = <1024>;
				vactive = <600>;
				hback-porch = <120>;
				hfront-porch = <120>;
				vback-porch = <17>;
				vfront-porch = <18>;
				hsync-len = <7>;
				vsync-len = <5>;
				hsync-active = <0>;
				vsync-active = <0>;
				de-active = <0>;
				pixelclk-active = <0>;
				swap-rb = <0>;
				swap-rg = <0>;
				swap-gb = <0>;
                     	};
                     	timing2: timing2 {
				screen-type = <SCREEN_RGB>;
				out-face    = <OUT_P888>;
				color-mode = <COLOR_YCBCR>;
				clock-frequency = <297000000>;
				hactive = <3840>;
				vactive = <2160>;
				hback-porch = <296>;
				hfront-porch = <176>;
				vback-porch = <72>;
				vfront-porch = <8>;
				hsync-len = <88>;
				vsync-len = <10>;
				hsync-active = <1>;
				vsync-active = <1>;
				de-active = <0>;
				pixelclk-active = <0>;
				swap-rb = <0>;
				swap-rg = <0>;
				swap-gb = <0>;
                     	};

                     	timing3: timing3{
				screen-type = <SCREEN_RGB>;
				out-face    = <OUT_P888>;
				color-mode = <COLOR_YCBCR>;
				clock-frequency = <148500000>;
				hactive = <1920>;
				vactive = <1080>;
				hback-porch = <148>;
				hfront-porch = <88>;
				vback-porch = <36>;
				vfront-porch = <4>;
				hsync-len = <44>;
				vsync-len = <5>;
				hsync-active = <1>;
				vsync-active = <1>;
				de-active = <0>;
				pixelclk-active = <0>;
				swap-rb = <0>;
				swap-rg = <0>;
				swap-gb = <0>;
                     	};
               };
};
